VERSION ""

NS_ :

BS_:

BU_: XXX

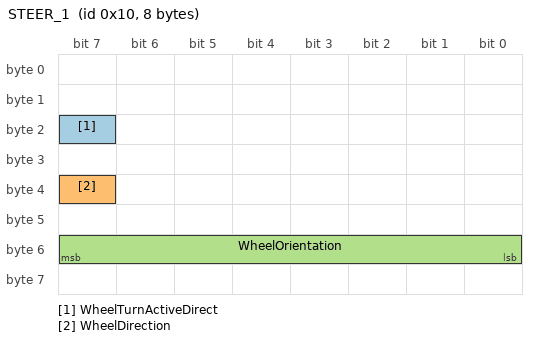
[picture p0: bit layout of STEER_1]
BO_ 16 STEER_1: 8 XXX
 SG_ WheelTurnActiveDirect : 23|1@0+ (1,0) [0|255] "" XXX
 SG_ WheelDirection : 39|1@0+ (1,0) [0|1] "" XXX
 SG_ WheelOrientation : 55|8@0+ (1,0) [0|255] "" XXX

CM_ SG_ 16 WheelTurnActiveDirect "0-wheel going ccw,1-wheel going cw";
CM_ SG_ 16 WheelDirection "0-left,1-right. ";
